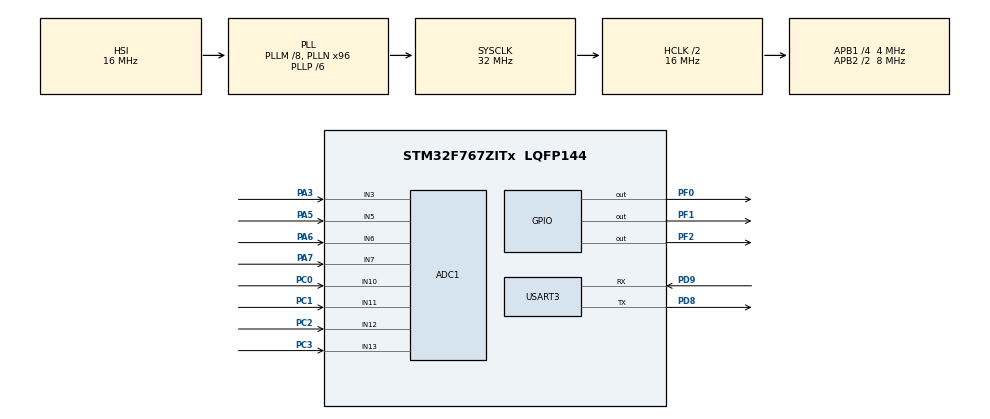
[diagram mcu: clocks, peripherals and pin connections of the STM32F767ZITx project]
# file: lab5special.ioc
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ADC1.Channel-0\#ChannelRegularConversion=ADC_CHANNEL_10
ADC1.ContinuousConvMode=ENABLE
ADC1.DMAContinuousRequests=ENABLE
ADC1.EOCSelection=ADC_EOC_SEQ_CONV
ADC1.NbrOfConversion=1
ADC1.NbrOfConversionFlag=1
ADC1.Rank-0\#ChannelRegularConversion=1
ADC1.SamplingTime-0\#ChannelRegularConversion=ADC_SAMPLETIME_3CYCLES
ADC1.master=1
CORTEX_M7.default_mode_Activation=1
Dma.ADC1.0.Direction=DMA_PERIPH_TO_MEMORY
Dma.ADC1.0.FIFOMode=DMA_FIFOMODE_DISABLE
Dma.ADC1.0.Instance=DMA2_Stream0
Dma.ADC1.0.MemDataAlignment=DMA_MDATAALIGN_HALFWORD
Dma.ADC1.0.MemInc=DMA_MINC_ENABLE
Dma.ADC1.0.Mode=DMA_CIRCULAR
Dma.ADC1.0.PeriphDataAlignment=DMA_PDATAALIGN_HALFWORD
Dma.ADC1.0.PeriphInc=DMA_PINC_DISABLE
Dma.ADC1.0.Priority=DMA_PRIORITY_LOW
Dma.Request0=ADC1
Mcu.Family=STM32F7
Mcu.Name=STM32F767ZITx
Mcu.Package=LQFP144
NVIC.DMA2_Stream0_IRQn=true\:0\:0\:false\:false\:true\:false\:true\:true
NVIC.PriorityGroup=NVIC_PRIORITYGROUP_4
PA3.Signal=ADCx_IN3
PA5.Signal=ADCx_IN5
PA6.Signal=ADCx_IN6
PA7.Signal=ADCx_IN7
PC0.Signal=ADCx_IN10
PC1.Signal=ADCx_IN11
PC2.Signal=ADCx_IN12
PC3.Signal=ADCx_IN13
PD8.Mode=Asynchronous
PD8.Signal=USART3_TX
PD9.Mode=Asynchronous
PD9.Signal=USART3_RX
PF0.Signal=GPIO_Output
PF1.Signal=GPIO_Output
PF2.Signal=GPIO_Output
ProjectManager.HeapSize=0x200
ProjectManager.StackSize=0x400
ProjectManager.TargetToolchain=STM32CubeIDE
RCC.AHBCLKDivider=RCC_SYSCLK_DIV2
RCC.AHBFreq_Value=16000000
RCC.APB1CLKDivider=RCC_HCLK_DIV4
RCC.APB1Freq_Value=4000000
RCC.APB1TimFreq_Value=8000000
RCC.APB2CLKDivider=RCC_HCLK_DIV2
RCC.APB2Freq_Value=8000000
RCC.APB2TimFreq_Value=16000000
RCC.CortexFreq_Value=16000000
RCC.HCLKFreq_Value=16000000
RCC.HSE_VALUE=25000000
RCC.HSI_VALUE=16000000
RCC.LSE_VALUE=32768
RCC.PLLM=8
RCC.PLLN=96
RCC.PLLP=RCC_PLLP_DIV6
RCC.SYSCLKFreq_VALUE=32000000
RCC.SYSCLKSource=RCC_SYSCLKSOURCE_PLLCLK
RCC.USBFreq_Value=96000000
RCC.VCOOutputFreq_Value=192000000
SH.ADCx_IN10.0=ADC1_IN10,IN10
SH.ADCx_IN11.0=ADC1_IN11,IN11
SH.ADCx_IN12.0=ADC1_IN12,IN12
SH.ADCx_IN13.0=ADC1_IN13,IN13
SH.ADCx_IN3.0=ADC1_IN3,IN3
SH.ADCx_IN5.0=ADC1_IN5,IN5
SH.ADCx_IN6.0=ADC1_IN6,IN6
SH.ADCx_IN7.0=ADC1_IN7,IN7
USART3.VirtualMode-Asynchronous=VM_ASYNC
board=custom

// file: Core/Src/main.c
/* USER CODE BEGIN Header */
/**
  ******************************************************************************
  * @file           : main.c
  * @brief          : Main program body
  ******************************************************************************
  * @attention
  *
  * Copyright (c) 2024 STMicroelectronics.
  * All rights reserved.
  *
  * This software is licensed under terms that can be found in the LICENSE file
  * in the root directory of this software component.
  * If no LICENSE file comes with this software, it is provided AS-IS.
  *
  ******************************************************************************
  */
/* USER CODE END Header */
#include "main.h"
#include "adc.h"
#include "dma.h"
#include "usart.h"
#include "gpio.h"

void SystemClock_Config(void);
static void MPU_Config(void);

int main(void)
{

  /* USER CODE BEGIN 1 */
	MPU_Config();

	  /* MCU Configuration--------------------------------------------------------*/
    /* MCU Configuration--------------------------------------------------------*/
    HAL_Init();
    SystemClock_Config();

    /* Initialize all configured peripherals */
    MX_GPIO_Init();
    MX_DMA_Init();
    MX_ADC1_Init();

    /* Start ADC conversion with DMA */
    HAL_ADC_Start_DMA(&hadc1, (uint32_t*)adc_values, 8);

    /* Infinite loop */
    while (1)
    {
        // Main loop does nothing, all work done in DMA callbacks
    }
}

/* ADC1 init function */
static void MX_ADC1_Init(void)
{
    ADC_ChannelConfTypeDef sConfig = {0};

    /* Configure the global features of the ADC (Clock, Resolution, Data Alignment and number of conversion) */
    hadc1.Instance = ADC1;
    hadc1.Init.ClockPrescaler = ADC_CLOCK_SYNC_PCLK_DIV4;
    hadc1.Init.Resolution = ADC_RESOLUTION_12B;
    hadc1.Init.ScanConvMode = ADC_SCAN_ENABLE;
    hadc1.Init.ContinuousConvMode = DISABLE;
    hadc1.Init.DiscontinuousConvMode = DISABLE;
    hadc1.Init.ExternalTrigConvEdge = ADC_EXTERNALTRIGCONVEDGE_NONE;
    hadc1.Init.ExternalTrigConv = ADC_SOFTWARE_START;
    hadc1.Init.DataAlign = ADC_DATAALIGN_RIGHT;
    hadc1.Init.NbrOfConversion = 8;
    hadc1.Init.DMAContinuousRequests = ENABLE;
    hadc1.Init.EOCSelection = ADC_EOC_SINGLE_CONV;
    HAL_ADC_Init(&hadc1);

    /* Configure for the selected ADC regular channel its corresponding rank in the sequencer and its sample time */
    sConfig.Channel = ADC_CHANNEL_0;  // Adjust the channel as needed
    sConfig.Rank = 1;
    sConfig.SamplingTime = ADC_SAMPLETIME_3CYCLES;
    HAL_ADC_ConfigChannel(&hadc1, &sConfig);

    // Repeat the above for other channels (1, 2, ..., 7)
}

/* DMA controller clock enable */
static void MX_DMA_Init(void)
{
    __HAL_RCC_DMA2_CLK_ENABLE();

    /* Configure DMA request hdma_adc1 on DMA2_Stream0 */
    hdma_adc1.Instance = DMA2_Stream0;
    hdma_adc1.Init.Channel = DMA_CHANNEL_0;
    hdma_adc1.Init.Direction = DMA_PERIPH_TO_MEMORY;
    hdma_adc1.Init.PeriphInc = DMA_PINC_DISABLE;
    hdma_adc1.Init.MemInc = DMA_MINC_ENABLE;
    hdma_adc1.Init.PeriphDataAlignment = DMA_PDATAALIGN_WORD;
    hdma_adc1.Init.MemDataAlignment = DMA_MDATAALIGN_WORD;
    hdma_adc1.Init.Mode = DMA_CIRCULAR;
    hdma_adc1.Init.Priority = DMA_PRIORITY_LOW;
    hdma_adc1.Init.FIFOMode = DMA_FIFOMODE_DISABLE;
    HAL_DMA_Init(&hdma_adc1);

    __HAL_LINKDMA(&hadc1, DMA_Handle, hdma_adc1);

    /* Configure NVIC for DMA */
    HAL_NVIC_SetPriority(DMA2_Stream0_IRQn, 0, 0);
    HAL_NVIC_EnableIRQ(DMA2_Stream0_IRQn);
}

/* GPIO init function */
static void MX_GPIO_Init(void)
{
    __HAL_RCC_GPIOB_CLK_ENABLE();
    GPIO_InitTypeDef GPIO_InitStruct = {0};

    /*Configure GPIO pin : LED Pin */
    GPIO_InitStruct.Pin = GPIO_PIN_0; // Adjust the pin number for LD2
    GPIO_InitStruct.Mode = GPIO_MODE_OUTPUT_PP;
    GPIO_InitStruct.Pull = GPIO_NOPULL;
    GPIO_InitStruct.Speed = GPIO_SPEED_FREQ_LOW;
    HAL_GPIO_Init(GPIOB, &GPIO_InitStruct);
}

/* Callback for ADC conversion half complete */
void HAL_ADC_ConvHalfCpltCallback(ADC_HandleTypeDef* hadc)
{
    if (hadc->Instance == ADC1)
    {
        HAL_GPIO_WritePin(GPIOB, GPIO_PIN_0, GPIO_PIN_SET); // Turn on LD2
    }
}

/* Callback for ADC conversion complete */
void HAL_ADC_ConvCpltCallback(ADC_HandleTypeDef* hadc)
{
    if (hadc->Instance == ADC1)
    {
        HAL_GPIO_WritePin(GPIOB, GPIO_PIN_0, GPIO_PIN_RESET); // Turn off LD2
    }
}
  /* USER CODE END 1 */

  /* MPU Configuration--------------------------------------------------------*/
  MPU_Config();

  /* MCU Configuration--------------------------------------------------------*/

  /* Reset of all peripherals, Initializes the Flash interface and the Systick. */
  HAL_Init();

  /* Configure the system clock */
  SystemClock_Config();

  /* Initialize all configured peripherals */
  MX_GPIO_Init();
  MX_DMA_Init();
  MX_ADC1_Init();
  MX_USART3_UART_Init();

  /* Infinite loop */
  while (1)
  {

  }
}

void SystemClock_Config(void)
{
  RCC_OscInitTypeDef RCC_OscInitStruct = {0};
  RCC_ClkInitTypeDef RCC_ClkInitStruct = {0};

  /** Configure the main internal regulator output voltage
  */
  __HAL_RCC_PWR_CLK_ENABLE();
  __HAL_PWR_VOLTAGESCALING_CONFIG(PWR_REGULATOR_VOLTAGE_SCALE3);

  /** Initializes the RCC Oscillators according to the specified parameters
  * in the RCC_OscInitTypeDef structure.
  */
  RCC_OscInitStruct.OscillatorType = RCC_OSCILLATORTYPE_HSI;
  RCC_OscInitStruct.HSIState = RCC_HSI_ON;
  RCC_OscInitStruct.HSICalibrationValue = RCC_HSICALIBRATION_DEFAULT;
  RCC_OscInitStruct.PLL.PLLState = RCC_PLL_ON;
  RCC_OscInitStruct.PLL.PLLSource = RCC_PLLSOURCE_HSI;
  RCC_OscInitStruct.PLL.PLLM = 8;
  RCC_OscInitStruct.PLL.PLLN = 96;
  RCC_OscInitStruct.PLL.PLLP = RCC_PLLP_DIV6;
  RCC_OscInitStruct.PLL.PLLQ = 2;
  RCC_OscInitStruct.PLL.PLLR = 2;
  if (HAL_RCC_OscConfig(&RCC_OscInitStruct) != HAL_OK)
  {
    Error_Handler();
  }

  /** Initializes the CPU, AHB and APB buses clocks
  */
  RCC_ClkInitStruct.ClockType = RCC_CLOCKTYPE_HCLK|RCC_CLOCKTYPE_SYSCLK
                              |RCC_CLOCKTYPE_PCLK1|RCC_CLOCKTYPE_PCLK2;
  RCC_ClkInitStruct.SYSCLKSource = RCC_SYSCLKSOURCE_PLLCLK;
  RCC_ClkInitStruct.AHBCLKDivider = RCC_SYSCLK_DIV2;
  RCC_ClkInitStruct.APB1CLKDivider = RCC_HCLK_DIV4;
  RCC_ClkInitStruct.APB2CLKDivider = RCC_HCLK_DIV2;

  if (HAL_RCC_ClockConfig(&RCC_ClkInitStruct, FLASH_LATENCY_0) != HAL_OK)
  {
    Error_Handler();
  }
}

 /* MPU Configuration */

void MPU_Config(void)
{
  MPU_Region_InitTypeDef MPU_InitStruct = {0};

  /* Disables the MPU */
  HAL_MPU_Disable();

  /** Initializes and configures the Region and the memory to be protected
  */
  MPU_InitStruct.Enable = MPU_REGION_ENABLE;
  MPU_InitStruct.Number = MPU_REGION_NUMBER0;
  MPU_InitStruct.BaseAddress = 0x0;
  MPU_InitStruct.Size = MPU_REGION_SIZE_4GB;
  MPU_InitStruct.SubRegionDisable = 0x87;
  MPU_InitStruct.TypeExtField = MPU_TEX_LEVEL0;
  MPU_InitStruct.AccessPermission = MPU_REGION_NO_ACCESS;
  MPU_InitStruct.DisableExec = MPU_INSTRUCTION_ACCESS_DISABLE;
  MPU_InitStruct.IsShareable = MPU_ACCESS_SHAREABLE;
  MPU_InitStruct.IsCacheable = MPU_ACCESS_NOT_CACHEABLE;
  MPU_InitStruct.IsBufferable = MPU_ACCESS_NOT_BUFFERABLE;

  HAL_MPU_ConfigRegion(&MPU_InitStruct);
  /* Enables the MPU */
  HAL_MPU_Enable(MPU_PRIVILEGED_DEFAULT);

}

void Error_Handler(void)
{
  __disable_irq();
  while (1)
  {
  }
}
